# CC3200 register map
Vendor: Texas Instruments; Series: SimpleLink; File version: 1.0
CPU: CM4 r0p1, little endian, MPU, no FPU, 3 interrupt priority bits
Registers are 32-bit, read-write, reset 0x0 unless marked. A register's access mark holds for its fields unless they carry their own. Offsets are from the block's base; [hi:lo] are bit positions; {n}, {i} and the like mark numbered series.

## MCASP — I2S
Base 0x4401C000
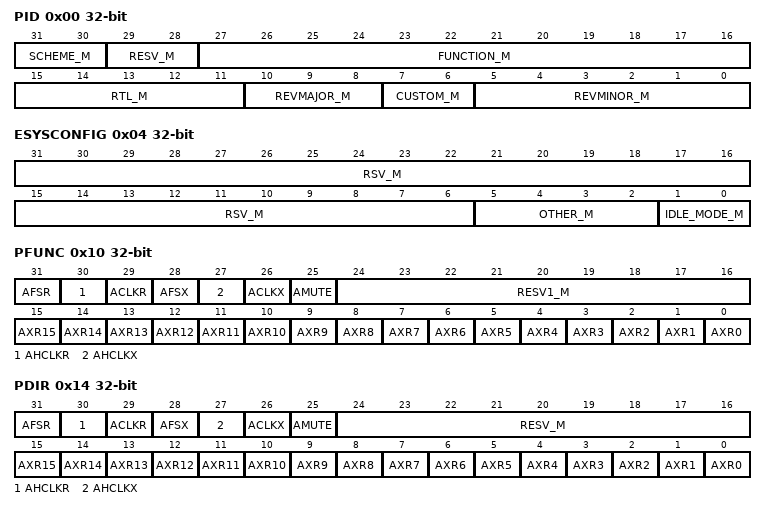
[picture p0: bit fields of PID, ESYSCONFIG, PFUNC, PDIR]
0x00 PID — MCASP_PID
  [31:30] SCHEME_M — MCASP_PID
  [29:28] RESV_M — MCASP_PID
  [27:16] FUNCTION_M — MCASP_PID
  [15:11] RTL_M — MCASP_PID
  [10:8] REVMAJOR_M — MCASP_PID
  [7:6] CUSTOM_M — MCASP_PID
  [5:0] REVMINOR_M — MCASP_PID
0x04 ESYSCONFIG — MCASP_ESYSCONFIG
  [31:6] RSV_M — MCASP_ESYSCONFIG
  [5:2] OTHER_M — MCASP_ESYSCONFIG
  [1:0] IDLE_MODE_M — MCASP_ESYSCONFIG
0x10 PFUNC — MCASP_PFUNC
  [31] AFSR — MCASP_PFUNC
  [30] AHCLKR — MCASP_PFUNC
  [29] ACLKR — MCASP_PFUNC
  [28] AFSX — MCASP_PFUNC
  [27] AHCLKX — MCASP_PFUNC
  [26] ACLKX — MCASP_PFUNC
  [25] AMUTE — MCASP_PFUNC
  [24:16] RESV1_M — MCASP_PFUNC
  [n] AXR{n} (n=0..15) — MCASP_PFUNC
0x14 PDIR — MCASP_PDIR
  [31] AFSR — MCASP_PDIR
  [30] AHCLKR — MCASP_PDIR
  [29] ACLKR — MCASP_PDIR
  [28] AFSX — MCASP_PDIR
  [27] AHCLKX — MCASP_PDIR
  [26] ACLKX — MCASP_PDIR
  [25] AMUTE — MCASP_PDIR
  [24:16] RESV_M — MCASP_PDIR
  [n] AXR{n} (n=0..15) — MCASP_PDIR
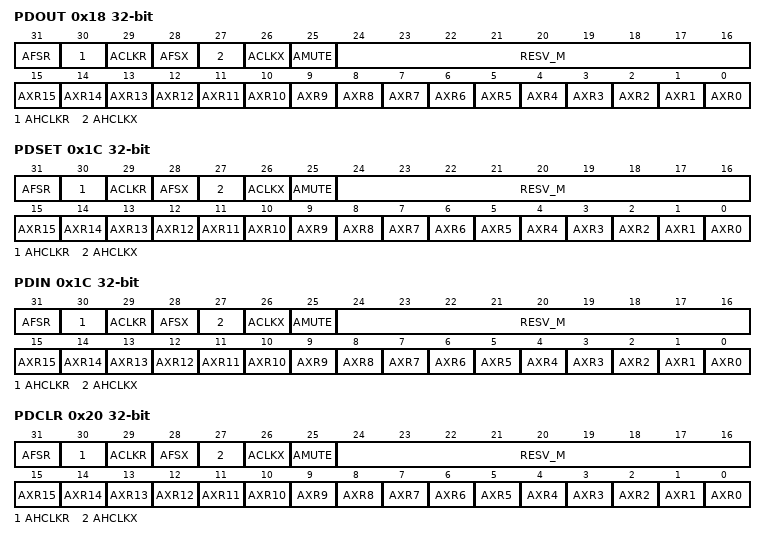
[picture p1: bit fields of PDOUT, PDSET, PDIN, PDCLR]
0x18 PDOUT — MCASP_PDOUT
  [31] AFSR — MCASP_PDOUT
  [30] AHCLKR — MCASP_PDOUT
  [29] ACLKR — MCASP_PDOUT
  [28] AFSX — MCASP_PDOUT
  [27] AHCLKX — MCASP_PDOUT
  [26] ACLKX — MCASP_PDOUT
  [25] AMUTE — MCASP_PDOUT
  [24:16] RESV_M — MCASP_PDOUT
  [n] AXR{n} (n=0..15) — MCASP_PDOUT
0x1C PDSET — MCASP_PDSET
  [31] AFSR — MCASP_PDSET
  [30] AHCLKR — MCASP_PDSET
  [29] ACLKR — MCASP_PDSET
  [28] AFSX — MCASP_PDSET
  [27] AHCLKX — MCASP_PDSET
  [26] ACLKX — MCASP_PDSET
  [25] AMUTE — MCASP_PDSET
  [24:16] RESV_M — MCASP_PDSET
  [n] AXR{n} (n=0..15) — MCASP_PDSET
0x1C PDIN — MCASP_PDIN
  [31] AFSR — MCASP_PDIN
  [30] AHCLKR — MCASP_PDIN
  [29] ACLKR — MCASP_PDIN
  [28] AFSX — MCASP_PDIN
  [27] AHCLKX — MCASP_PDIN
  [26] ACLKX — MCASP_PDIN
  [25] AMUTE — MCASP_PDIN
  [24:16] RESV_M — MCASP_PDIN
  [n] AXR{n} (n=0..15) — MCASP_PDIN
0x20 PDCLR — MCASP_PDCLR
  [31] AFSR — MCASP_PDCLR
  [30] AHCLKR — MCASP_PDCLR
  [29] ACLKR — MCASP_PDCLR
  [28] AFSX — MCASP_PDCLR
  [27] AHCLKX — MCASP_PDCLR
  [26] ACLKX — MCASP_PDCLR
  [25] AMUTE — MCASP_PDCLR
  [24:16] RESV_M — MCASP_PDCLR
  [n] AXR{n} (n=0..15) — MCASP_PDCLR
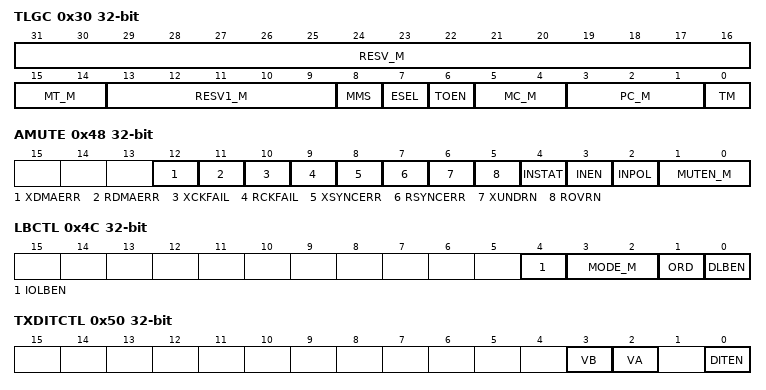
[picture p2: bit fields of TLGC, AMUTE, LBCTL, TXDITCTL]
0x30 TLGC — MCASP_TLGC
  [31:16] RESV_M — MCASP_TLGC
  [15:14] MT_M — MCASP_TLGC
  [13:9] RESV1_M — MCASP_TLGC
  [8] MMS — MCASP_TLGC
  [7] ESEL — MCASP_TLGC
  [6] TOEN — MCASP_TLGC
  [5:4] MC_M — MCASP_TLGC
  [3:1] PC_M — MCASP_TLGC
  [0] TM — MCASP_TLGC
0x34 TLMR — MCASP_TLMR
  [31:0] TLMR_M
0x38 TLEC — MCASP_TLEC
  [31:0] TLEC_M
0x44 GBLCTL — MCASP_GBLCTL
  [12] XFRST — MCASP_GBLCTL
  [12] _XFRST — MCASP_GBLCTL
  [12] _XFRST_2 — MCASP_GBLCTL
  [11] XSMRST — MCASP_GBLCTL
  [11] _XSMRST — MCASP_GBLCTL
  [11] _XSMRST_2 — MCASP_GBLCTL
  [10] XSRCLR — MCASP_GBLCTL
  [10] _XSRCLR — MCASP_GBLCTL
  [10] _XSRCLR_2 — MCASP_GBLCTL
  [9] XHCLKRST — MCASP_GBLCTL
  [9] _XHCLKRST — MCASP_GBLCTL
  [9] _XHCLKRST_2 — MCASP_GBLCTL
  [8] XCLKRST — MCASP_GBLCTL
  [8] _XCLKRST — MCASP_GBLCTL
  [8] _XCLKRST_2 — MCASP_GBLCTL
  [4] RFRST — MCASP_GBLCTL
  [4] _RFRST — MCASP_GBLCTL
  [4] _RFRST_2 — MCASP_GBLCTL
  [3] RSMRST — MCASP_GBLCTL
  [3] _RSMRST — MCASP_GBLCTL
  [3] _RSMRST_2 — MCASP_GBLCTL
  [2] RSRCLR — MCASP_GBLCTL
  [2] _RSRCLR — MCASP_GBLCTL
  [2] _RSRCLKR — MCASP_GBLCTL
  [1] RHCLKRST — MCASP_GBLCTL
  [1] _RHCLKRST — MCASP_GBLCTL
  [1] _RHCLKRST_2 — MCASP_GBLCTL
  [0] RCLKRST — MCASP_GBLCTL
  [0] _RCLKRST — MCASP_GBLCTL
  [0] _RCLKRST_2 — MCASP_GBLCTL
0x48 AMUTE — MCASP_AMUTE
  [12] XDMAERR — MCASP_AMUTE
  [11] RDMAERR — MCASP_AMUTE
  [10] XCKFAIL — MCASP_AMUTE
  [9] RCKFAIL — MCASP_AMUTE
  [8] XSYNCERR — MCASP_AMUTE
  [7] RSYNCERR — MCASP_AMUTE
  [6] XUNDRN — MCASP_AMUTE
  [5] ROVRN — MCASP_AMUTE
  [4] INSTAT — MCASP_AMUTE
  [3] INEN — MCASP_AMUTE
  [2] INPOL — MCASP_AMUTE
  [1:0] MUTEN_M — MCASP_AMUTE
0x4C LBCTL — MCASP_LBCTL
  [4] IOLBEN — MCASP_LBCTL
  [3:2] MODE_M — MCASP_LBCTL
  [1] ORD — MCASP_LBCTL
  [0] DLBEN — MCASP_LBCTL
0x50 TXDITCTL — MCASP_TXDITCTL
  [3] VB — MCASP_TXDITCTL
  [2] VA — MCASP_TXDITCTL
  [0] DITEN — MCASP_TXDITCTL
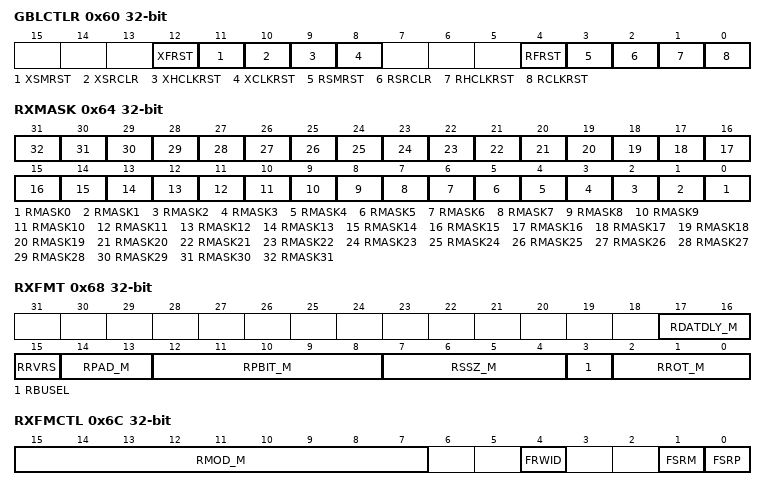
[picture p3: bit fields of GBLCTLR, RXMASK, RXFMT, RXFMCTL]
0x60 GBLCTLR — MCASP_GBLCTLR
  [12] XFRST — MCASP_GBLCTLR
  [11] XSMRST — MCASP_GBLCTLR
  [10] XSRCLR — MCASP_GBLCTLR
  [9] XHCLKRST — MCASP_GBLCTLR
  [8] XCLKRST — MCASP_GBLCTLR
  [4] RFRST — MCASP_GBLCTLR
  [3] RSMRST — MCASP_GBLCTLR
  [2] RSRCLR — MCASP_GBLCTLR
  [1] RHCLKRST — MCASP_GBLCTLR
  [0] RCLKRST — MCASP_GBLCTLR
0x64 RXMASK — MCASP_RXMASK
  [n] RMASK{n} (n=0..31) — MCASP_RXMASK
0x68 RXFMT — MCASP_RXFMT
  [17:16] RDATDLY_M — MCASP_RXFMT
  [15] RRVRS — MCASP_RXFMT
  [14:13] RPAD_M — MCASP_RXFMT
  [12:8] RPBIT_M — MCASP_RXFMT
  [7:4] RSSZ_M — MCASP_RXFMT
  [3] RBUSEL — MCASP_RXFMT
  [2:0] RROT_M — MCASP_RXFMT
0x6C RXFMCTL — MCASP_RXFMCTL
  [15:7] RMOD_M — MCASP_RXFMCTL
  [4] FRWID — MCASP_RXFMCTL
  [1] FSRM — MCASP_RXFMCTL
  [0] FSRP — MCASP_RXFMCTL
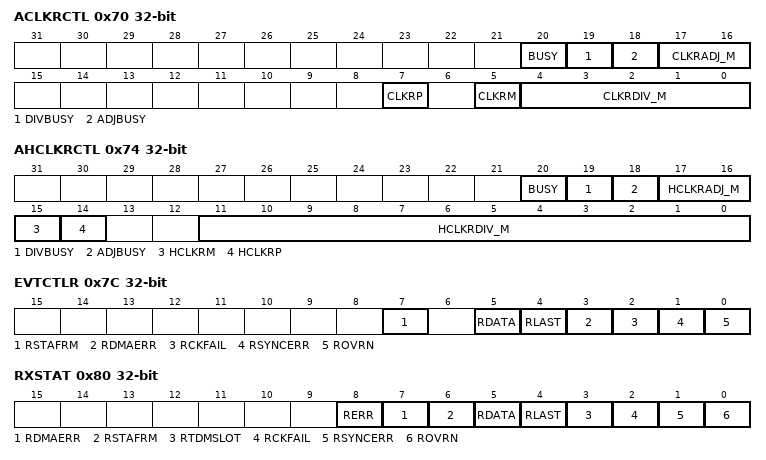
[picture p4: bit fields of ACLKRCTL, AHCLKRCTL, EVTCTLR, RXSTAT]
0x70 ACLKRCTL — MCASP_ACLKRCTL
  [20] BUSY — MCASP_ACLKRCTL
  [19] DIVBUSY — MCASP_ACLKRCTL
  [18] ADJBUSY — MCASP_ACLKRCTL
  [17:16] CLKRADJ_M — MCASP_ACLKRCTL
  [7] CLKRP — MCASP_ACLKRCTL
  [5] CLKRM — MCASP_ACLKRCTL
  [4:0] CLKRDIV_M — MCASP_ACLKRCTL
0x74 AHCLKRCTL — MCASP_AHCLKRCTL
  [20] BUSY — MCASP_AHCLKRCTL
  [19] DIVBUSY — MCASP_AHCLKRCTL
  [18] ADJBUSY — MCASP_AHCLKRCTL
  [17:16] HCLKRADJ_M — MCASP_AHCLKRCTL
  [15] HCLKRM — MCASP_AHCLKRCTL
  [14] HCLKRP — MCASP_AHCLKRCTL
  [11:0] HCLKRDIV_M — MCASP_AHCLKRCTL
0x78 RXTDM — MCASP_RXTDM
  [n] RTDMS{n} (n=0..31) — MCASP_RXTDM
  [9:0] LOT_RSLOTCNT_M — MCASP_RXTDM
0x7C EVTCTLR — MCASP_EVTCTLR
  [7] RSTAFRM — MCASP_EVTCTLR
  [5] RDATA — MCASP_EVTCTLR
  [4] RLAST — MCASP_EVTCTLR
  [3] RDMAERR — MCASP_EVTCTLR
  [2] RCKFAIL — MCASP_EVTCTLR
  [1] RSYNCERR — MCASP_EVTCTLR
  [0] ROVRN — MCASP_EVTCTLR
0x80 RXSTAT — MCASP_RXSTAT
  [8] RERR — MCASP_RXSTAT
  [7] RDMAERR — MCASP_RXSTAT
  [6] RSTAFRM — MCASP_RXSTAT
  [5] RDATA — MCASP_RXSTAT
  [4] RLAST — MCASP_RXSTAT
  [3] RTDMSLOT — MCASP_RXSTAT
  [2] RCKFAIL — MCASP_RXSTAT
  [1] RSYNCERR — MCASP_RXSTAT
  [0] ROVRN — MCASP_RXSTAT
0x84 RXTDMSLOT — MCASP_RXTDMSLOT
  [9:0] RSLOTCNT_M
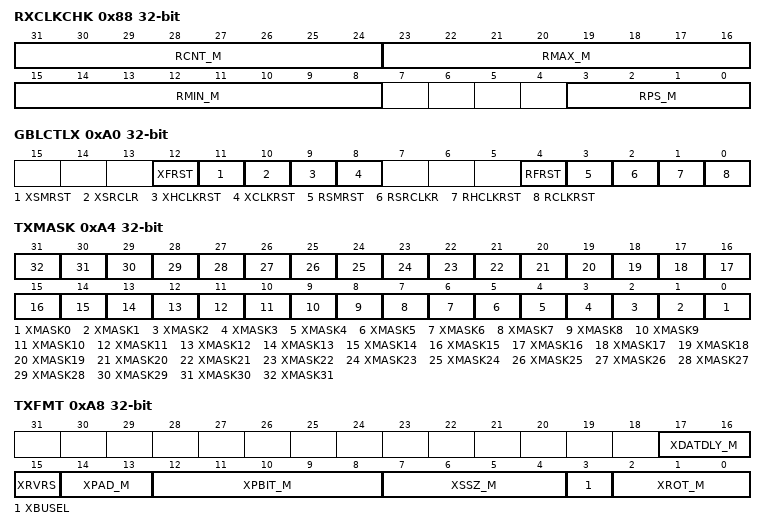
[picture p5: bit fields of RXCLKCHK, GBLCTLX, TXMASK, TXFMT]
0x88 RXCLKCHK — MCASP_RXCLKCHK
  [31:24] RCNT_M — MCASP_RXCLKCHK
  [23:16] RMAX_M — MCASP_RXCLKCHK
  [15:8] RMIN_M — MCASP_RXCLKCHK
  [3:0] RPS_M — MCASP_RXCLKCHK
0x8C REVTCTL — MCASP_REVTCTL
  [0] RDATDMA
0xA0 GBLCTLX — MCASP_GBLCTLX
  [12] XFRST — MCASP_GBLCTLX
  [11] XSMRST — MCASP_GBLCTLX
  [10] XSRCLR — MCASP_GBLCTLX
  [9] XHCLKRST — MCASP_GBLCTLX
  [8] XCLKRST — MCASP_GBLCTLX
  [4] RFRST — MCASP_GBLCTLX
  [3] RSMRST — MCASP_GBLCTLX
  [2] RSRCLKR — MCASP_GBLCTLX
  [1] RHCLKRST — MCASP_GBLCTLX
  [0] RCLKRST — MCASP_GBLCTLX
0xA4 TXMASK — MCASP_TXMASK
  [n] XMASK{n} (n=0..31) — MCASP_TXMASK
0xA8 TXFMT — MCASP_TXFMT
  [17:16] XDATDLY_M — MCASP_TXFMT
  [15] XRVRS — MCASP_TXFMT
  [14:13] XPAD_M — MCASP_TXFMT
  [12:8] XPBIT_M — MCASP_TXFMT
  [7:4] XSSZ_M — MCASP_TXFMT
  [3] XBUSEL — MCASP_TXFMT
  [2:0] XROT_M — MCASP_TXFMT
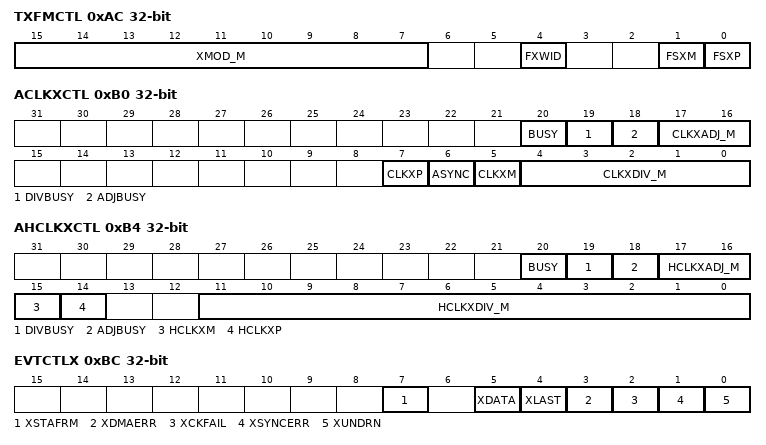
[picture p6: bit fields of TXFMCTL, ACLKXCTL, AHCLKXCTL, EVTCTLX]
0xAC TXFMCTL — MCASP_TXFMCTL
  [15:7] XMOD_M — MCASP_TXFMCTL
  [4] FXWID — MCASP_TXFMCTL
  [1] FSXM — MCASP_TXFMCTL
  [0] FSXP — MCASP_TXFMCTL
0xB0 ACLKXCTL — MCASP_ACLKXCTL
  [20] BUSY — MCASP_ACLKXCTL
  [19] DIVBUSY — MCASP_ACLKXCTL
  [18] ADJBUSY — MCASP_ACLKXCTL
  [17:16] CLKXADJ_M — MCASP_ACLKXCTL
  [7] CLKXP — MCASP_ACLKXCTL
  [6] ASYNC — MCASP_ACLKXCTL
  [5] CLKXM — MCASP_ACLKXCTL
  [4:0] CLKXDIV_M — MCASP_ACLKXCTL
0xB4 AHCLKXCTL — MCASP_AHCLKXCTL
  [20] BUSY — MCASP_AHCLKXCTL
  [19] DIVBUSY — MCASP_AHCLKXCTL
  [18] ADJBUSY — MCASP_AHCLKXCTL
  [17:16] HCLKXADJ_M — MCASP_AHCLKXCTL
  [15] HCLKXM — MCASP_AHCLKXCTL
  [14] HCLKXP — MCASP_AHCLKXCTL
  [11:0] HCLKXDIV_M — MCASP_AHCLKXCTL
0xB8 TXTDM — MCASP_TXTDM
  [n] XTDMS{n} (n=0..31) — MCASP_TXTDM
  [9:0] LOT_XSLOTCNT_M — MCASP_TXTDM
0xBC EVTCTLX — MCASP_EVTCTLX
  [7] XSTAFRM — MCASP_EVTCTLX
  [5] XDATA — MCASP_EVTCTLX
  [4] XLAST — MCASP_EVTCTLX
  [3] XDMAERR — MCASP_EVTCTLX
  [2] XCKFAIL — MCASP_EVTCTLX
  [1] XSYNCERR — MCASP_EVTCTLX
  [0] XUNDRN — MCASP_EVTCTLX
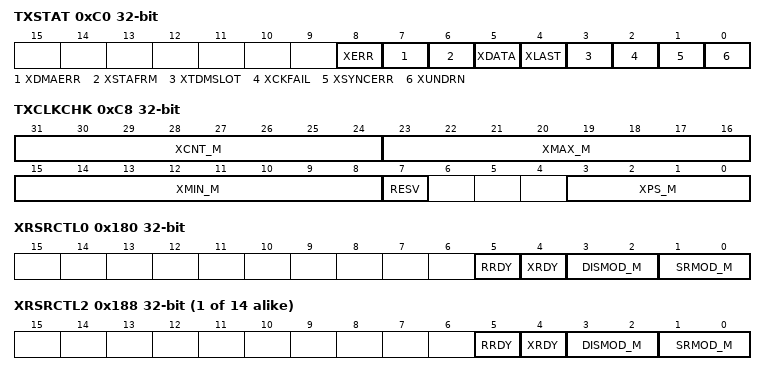
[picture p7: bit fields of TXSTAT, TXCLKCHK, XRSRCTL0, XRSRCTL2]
0xC0 TXSTAT — MCASP_TXSTAT
  [8] XERR — MCASP_TXSTAT
  [7] XDMAERR — MCASP_TXSTAT
  [6] XSTAFRM — MCASP_TXSTAT
  [5] XDATA — MCASP_TXSTAT
  [4] XLAST — MCASP_TXSTAT
  [3] XTDMSLOT — MCASP_TXSTAT
  [2] XCKFAIL — MCASP_TXSTAT
  [1] XSYNCERR — MCASP_TXSTAT
  [0] XUNDRN — MCASP_TXSTAT
0xC4 TXTDMSLOT — MCASP_TXTDMSLOT
  [9:0] XSLOTCNT_M
0xC8 TXCLKCHK — MCASP_TXCLKCHK
  [31:24] XCNT_M — MCASP_TXCLKCHK
  [23:16] XMAX_M — MCASP_TXCLKCHK
  [15:8] XMIN_M — MCASP_TXCLKCHK
  [7] RESV — MCASP_TXCLKCHK
  [3:0] XPS_M — MCASP_TXCLKCHK
0xCC XEVTCTL — MCASP_XEVTCTL
  [0] XDATDMA
0xD0 CLKADJEN — MCASP_CLKADJEN
  [0] ENABLE
{0x100+4i} DITCSRA{i} (i=0..5) — MCASP_DITCSRA{i}
  [31:0] DITCSRA{i}_M
{0x118+4i} DITCSRB{i} (i=0..5) — MCASP_DITCSRB{i}
  [31:0] DITCSRB{i}_M
{0x130+4i} DITUDRA{i} (i=0..5) — MCASP_DITUDRA{i}
  [31:0] DITUDRA{i}_M
{0x148+4i} DITUDRB{i} (i=0..5) — MCASP_DITUDRB{i}
  [31:0] DITUDRB{i}_M
0x180 XRSRCTL0 — MCASP_XRSRCTL0
  [5] RRDY — MCASP_XRSRCTL0
  [4] XRDY — MCASP_XRSRCTL0
  [3:2] DISMOD_M — MCASP_XRSRCTL0
  [1:0] SRMOD_M — MCASP_XRSRCTL0
0x184 XRSRCTL1 — MCASP_XRSRCTL1
  [5] RRDY — MCASP_XRSRCTL1
  [5] _RRDY — MCASP_XRSRCTL1
  [5] _RRDY_{n} (n=2..6) — MCASP_XRSRCTL1
  [4] XRDY — MCASP_XRSRCTL1
  [4] _XRDY — MCASP_XRSRCTL1
  [4] _XRDY_{n} (n=2..6) — MCASP_XRSRCTL1
  [3:2] DISMOD_M — MCASP_XRSRCTL1
  [3:2] _DISMOD_M — MCASP_XRSRCTL1
  [3:2] _DISMOD_M_{n} (n=2..6) — MCASP_XRSRCTL1
  [1:0] SRMOD_M — MCASP_XRSRCTL1
  [1:0] _SRMOD_M — MCASP_XRSRCTL1
  [1:0] _SRMOD_M_{n} (n=2..6) — MCASP_XRSRCTL1
{0x180+4i} XRSRCTL{i} (i=2..15) — MCASP_XRSRCTL{i}
  [5] RRDY — MCASP_XRSRCTL{i}
  [4] XRDY — MCASP_XRSRCTL{i}
  [3:2] DISMOD_M — MCASP_XRSRCTL{i}
  [1:0] SRMOD_M — MCASP_XRSRCTL{i}
0x200 TXBUF0 — MCASP_TXBUF0
  [31:0] XBUF0_M
0x204 TXBUF1 — MCASP_TXBUF1
  [31:0] XBUF1_M — MCASP_TXBUF1
  [31:0] _XBUF{n}_M (n=10..15) — MCASP_TXBUF1
{0x200+4i} TXBUF{i} (i=2..15) — MCASP_TXBUF{i}
  [31:0] XBUF{i}_M
0x280 RXBUF0 — MCASP_RXBUF0
  [31:0] RBUF0_M
0x284 RXBUF1 — MCASP_RXBUF1
  [31:0] RBUF1_M — MCASP_RXBUF1
  [31:0] _RBUF{n}_M (n=10..15) — MCASP_RXBUF1
{0x280+4i} RXBUF{i} (i=2..15) — MCASP_RXBUF{i}
  [31:0] RBUF{i}_M
